# STMP3770 register map
Vendor: Freescale Semiconductor (NXP); Series: STMP37xx; File version: 1.0
CPU: other r0p0, little endian, no MPU, no FPU, 2 interrupt priority bits
Registers are 32-bit, read-write, reset 0x0 unless marked. A register's access mark holds for its fields unless they carry their own. Offsets are from the block's base; [hi:lo] are bit positions.

## CLKCTRL — STMP3770 时钟控制单元 (CLKCTRL)，管理 480MHz USB PLL、CPU/HBUS/XBUS 总线分频、各外设时钟门控与分数分频器、时钟源旁路选择及系统软复位。
Base 0x80040000
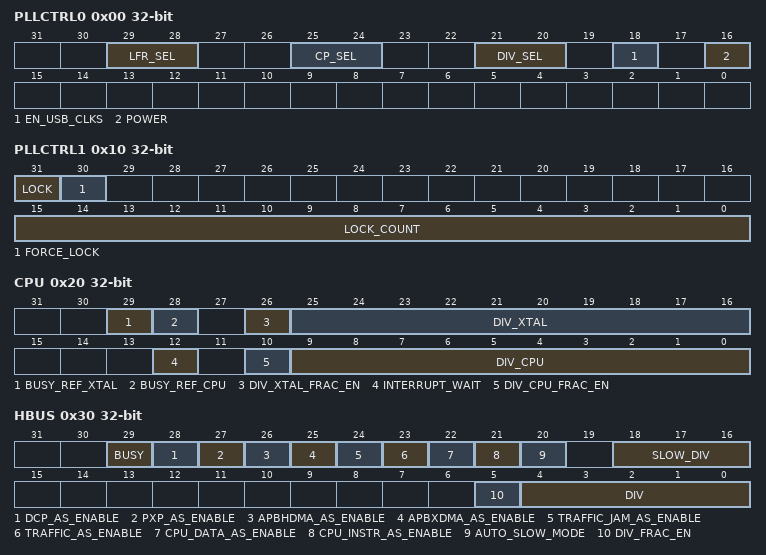
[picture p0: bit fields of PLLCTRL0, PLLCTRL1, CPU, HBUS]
0x00 PLLCTRL0 — 480MHz USB PLL 控制寄存器 0，控制 PLL 电源、USB 时钟输出使能及环路参数。
  [29:28] LFR_SEL — PLL 低频电阻选择，枚举值：DEFAULT=默认阻值，TIMES_2=2 倍阻值，TIMES_05=0.5 倍阻值，UNDEFINED=未定义。
    0=DEFAULT; 1=TIMES_2; 2=TIMES_05; 3=UNDEFINED
  [25:24] CP_SEL — PLL 电荷泵电流选择，枚举值：DEFAULT=默认电流，TIMES_2=2 倍电流，TIMES_05=0.5 倍电流，UNDEFINED=未定义。
    0=DEFAULT; 1=TIMES_2; 2=TIMES_05; 3=UNDEFINED
  [21:20] DIV_SEL — PLL 反馈分频选择，枚举值：DEFAULT=默认分频，LOWER=较低分频，LOWEST=最低分频，UNDEFINED=未定义。
    0=DEFAULT; 1=LOWER; 2=LOWEST; 3=UNDEFINED
  [18] EN_USB_CLKS — USB 时钟输出使能，置位后向 USB 模块提供 PLL 时钟。
  [16] POWER — PLL 电源使能，置位后启动 PLL 电路供电。
0x10 PLLCTRL1 — PLL 控制寄存器 1，保留寄存器，反映 PLL 锁定状态与锁定计数。
  [31] LOCK — PLL 锁定状态标志，只读，为 1 表示 PLL 已稳定锁定。
  [30] FORCE_LOCK — 强制锁定指示，置位后强制声明 PLL 锁定状态。
  [15:0] LOCK_COUNT — PLL 锁定计数器值，反映 PLL 从启动到锁定经历的计数周期。
0x20 CPU — CPU 时钟控制寄存器，配置 CPU 主时钟与晶振参考时钟的分频比。
  [29] BUSY_REF_XTAL — 晶振参考时钟分频忙标志，为 1 表示 DIV_XTAL 分频器正在更新。
  [28] BUSY_REF_CPU — CPU 参考时钟分频忙标志，为 1 表示 DIV_CPU 分频器正在更新。
  [26] DIV_XTAL_FRAC_EN — 晶振参考时钟分数分频使能，置位后启用 XTAL 路径分数分频模式。
  [25:16] DIV_XTAL — 晶振参考时钟整数分频值，用于 XTAL 旁路路径的分频。
  [12] INTERRUPT_WAIT — 中断等待模式使能，置位后 CPU 在时钟切换时等待中断完成。
  [10] DIV_CPU_FRAC_EN — CPU 时钟分数分频使能，置位后启用 CPU 分数分频模式。
  [9:0] DIV_CPU — CPU 时钟整数分频值，用于 PLL/分数时钟源路径的分频。
0x30 HBUS — AHB/APBH 总线时钟控制寄存器，配置 HBUS 分频及自动降速策略。
  [29] BUSY — HBUS 时钟分频忙标志，为 1 表示分频器正在更新。
  [28] DCP_AS_ENABLE — DCP 数据协处理器自动慢速模式使能，置位后允许 DCP 触发自动降速。
  [27] PXP_AS_ENABLE — PXP 像素处理器自动慢速模式使能，置位后允许 PXP 触发自动降速。
  [26] APBHDMA_AS_ENABLE — APBH DMA 自动慢速模式使能，置位后允许 APBH DMA 触发自动降速。
  [25] APBXDMA_AS_ENABLE — APBX DMA 自动慢速模式使能，置位后允许 APBX DMA 触发自动降速。
  [24] TRAFFIC_JAM_AS_ENABLE — 总线拥塞自动慢速模式使能，置位后允许总线拥塞触发自动降速。
  [23] TRAFFIC_AS_ENABLE — 总线流量自动慢速模式使能，置位后允许总线流量触发自动降速。
  [22] CPU_DATA_AS_ENABLE — CPU 数据访问自动慢速模式使能，置位后允许 CPU 数据访问触发自动降速。
  [21] CPU_INSTR_AS_ENABLE — CPU 指令访问自动慢速模式使能，置位后允许 CPU 取指触发自动降速。
  [20] AUTO_SLOW_MODE — 自动慢速模式使能，置位后根据总线负载自动降低 HBUS 频率。
  [18:16] SLOW_DIV — AHB 总线慢速分频选择，枚举值：BY1=1 分频，BY2=2 分频，BY4=4 分频，BY8=8 分频，BY16=16 分频，BY32=32 分频。
    0=BY1; 1=BY2; 2=BY4; 3=BY8; 4=BY16; 5=BY32
  [5] DIV_FRAC_EN — AHB 总线分数分频使能，置位后启用 HBUS 分数分频模式。
  [4:0] DIV — AHB 总线整数分频值，决定 HBUS 相对于参考源的时钟频率。
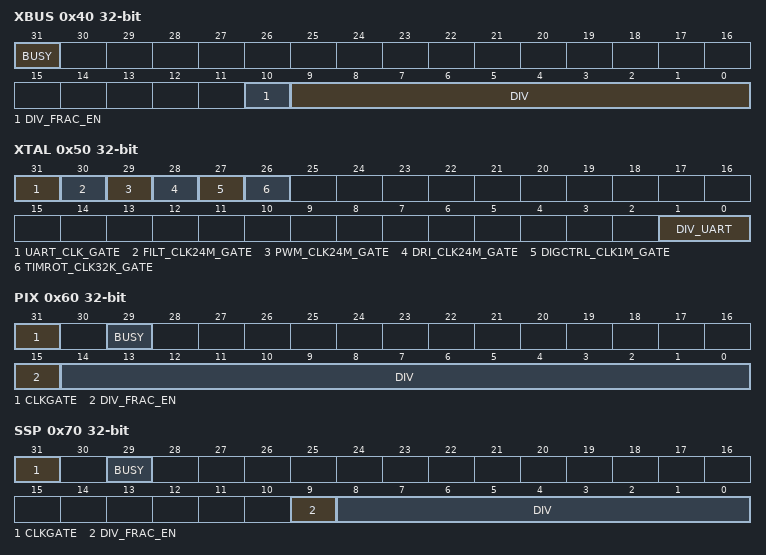
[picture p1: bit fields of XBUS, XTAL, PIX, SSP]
0x40 XBUS — APBX 总线时钟控制寄存器，配置 APBX 外设总线时钟分频。
  [31] BUSY — APBX 时钟分频忙标志，为 1 表示分频器正在更新。
  [10] DIV_FRAC_EN — APBX 总线分数分频使能，置位后启用 APBX 分数分频模式。
  [9:0] DIV — APBX 总线整数分频值，决定 APBX 相对于参考源的时钟频率。
0x50 XTAL — 24MHz 晶振时钟门控寄存器，控制各模块从 XTAL 获取的时钟门控。
  [31] UART_CLK_GATE — UART 时钟总门控，置位后关闭 UART 模块的晶振时钟。
  [30] FILT_CLK24M_GATE — FILT 24MHz 时钟门控，置位后关闭 FILT 模块的 24MHz 时钟。
  [29] PWM_CLK24M_GATE — PWM 24MHz 时钟门控，置位后关闭 PWM 模块的 24MHz 时钟。
  [28] DRI_CLK24M_GATE — DRI 24MHz 时钟门控，置位后关闭 DRI 模块的 24MHz 时钟。
  [27] DIGCTRL_CLK1M_GATE — DIGCTRL 1MHz 时钟门控，置位后关闭 DIGCTRL 模块的 1MHz 时钟。
  [26] TIMROT_CLK32K_GATE — TIMROT 32kHz 时钟门控，置位后关闭 TIMROT 模块的 32kHz 时钟。
  [1:0] DIV_UART — UART 晶振时钟分频值，决定 UART 模块从 24MHz 晶振获取的时钟分频比。
0x60 PIX — LCDIF 像素时钟控制寄存器，配置显示像素时钟分频与门控。
  [31] CLKGATE — PIX 时钟门控，置位后关闭 LCDIF 像素时钟输出。
  [29] BUSY — PIX 时钟分频忙标志，为 1 表示分频器正在更新。
  [15] DIV_FRAC_EN — PIX 像素时钟分数分频使能，置位后启用 PIX 分数分频模式。
  [14:0] DIV — PIX 像素时钟整数分频值，决定 LCDIF 像素时钟频率。
0x70 SSP — SSP 同步串行端口时钟控制寄存器，配置 SSP 外设时钟分频与门控。
  [31] CLKGATE — SSP 时钟门控，置位后关闭 SSP 外设时钟。
  [29] BUSY — SSP 时钟分频忙标志，为 1 表示分频器正在更新。
  [9] DIV_FRAC_EN — SSP 时钟分数分频使能，置位后启用 SSP 分数分频模式。
  [8:0] DIV — SSP 时钟整数分频值，决定 SSP 外设时钟频率。
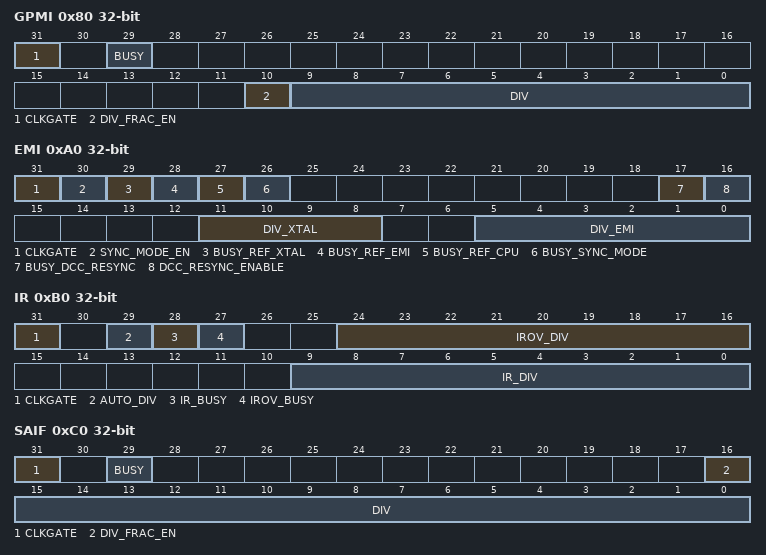
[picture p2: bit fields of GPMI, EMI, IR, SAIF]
0x80 GPMI — GPMI 通用媒体接口时钟控制寄存器，配置 GPMI 外设时钟分频与门控。
  [31] CLKGATE — GPMI 时钟门控，置位后关闭 GPMI 外设时钟。
  [29] BUSY — GPMI 时钟分频忙标志，为 1 表示分频器正在更新。
  [10] DIV_FRAC_EN — GPMI 时钟分数分频使能，置位后启用 GPMI 分数分频模式。
  [9:0] DIV — GPMI 时钟整数分频值，决定 GPMI 外设时钟频率。
0x90 SPDIF — SPDIF 数字音频接口时钟控制寄存器，仅含时钟门控控制。
  [31] CLKGATE — SPDIF 时钟门控，置位后关闭 SPDIF 模块时钟。
0xA0 EMI — EMI 外部存储器接口时钟控制寄存器，配置 EMI 时钟分频与同步模式。
  [31] CLKGATE — EMI 时钟门控，置位后关闭 EMI 模块时钟。
  [30] SYNC_MODE_EN — EMI 同步模式使能，置位后启用 EMI 同步时钟模式。
  [29] BUSY_REF_XTAL — 晶振参考时钟忙标志，为 1 表示 EMI 的 XTAL 参考分频器正在更新。
  [28] BUSY_REF_EMI — EMI 参考时钟忙标志，为 1 表示 EMI 参考分频器正在更新。
  [27] BUSY_REF_CPU — CPU 参考时钟忙标志，为 1 表示 EMI 的 CPU 参考分频器正在更新。
  [26] BUSY_SYNC_MODE — 同步模式忙标志，为 1 表示 EMI 同步模式切换正在进行。
  [17] BUSY_DCC_RESYNC — DCC 重同步忙标志，为 1 表示 DCC 重同步操作正在进行。
  [16] DCC_RESYNC_ENABLE — DCC 重同步使能，置位后启用 EMI 动态时钟校准重同步功能。
  [11:8] DIV_XTAL — EMI 晶振参考时钟整数分频值，用于 XTAL 旁路路径的分频。
  [5:0] DIV_EMI — EMI 时钟整数分频值，决定 EMI 相对于参考源的时钟频率。
0xB0 IR — 红外接口时钟控制寄存器，配置 IR 与 IROV 时钟分频及门控。
  [31] CLKGATE — IR 时钟门控，置位后关闭红外接口时钟。
  [29] AUTO_DIV — IR 自动分频使能，置位后启用 IR 时钟自动分频模式。
  [28] IR_BUSY — IR 时钟分频忙标志，为 1 表示 IR 分频器正在更新。
  [27] IROV_BUSY — IROV 时钟分频忙标志，为 1 表示 IROV 分频器正在更新。
  [24:16] IROV_DIV — IROV 红外过采样时钟整数分频值，决定红外过采样时钟频率。
  [9:0] IR_DIV — IR 红外时钟整数分频值，决定红外接口时钟频率。
0xC0 SAIF — SAIF 音频接口时钟控制寄存器，配置 SAIF 时钟分频与门控。
  [31] CLKGATE — SAIF 时钟门控，置位后关闭 SAIF 音频接口时钟。
  [29] BUSY — SAIF 时钟分频忙标志，为 1 表示分频器正在更新。
  [16] DIV_FRAC_EN — SAIF 时钟分数分频使能，置位后启用 SAIF 分数分频模式。
  [15:0] DIV — SAIF 时钟整数分频值，决定 SAIF 音频接口时钟频率。
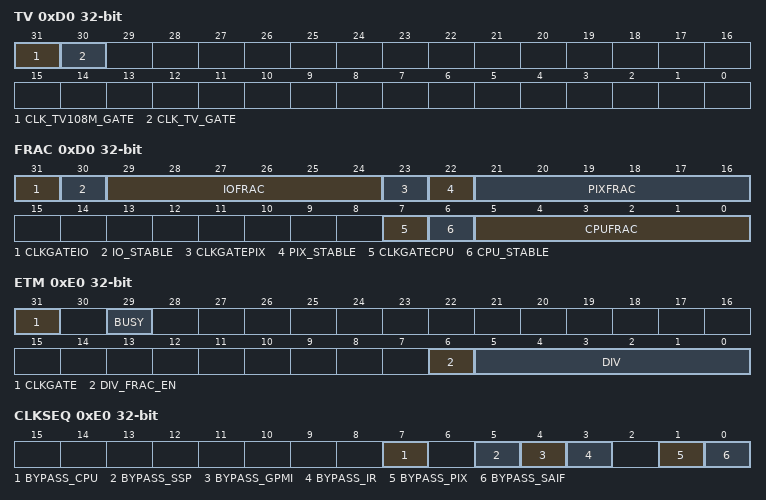
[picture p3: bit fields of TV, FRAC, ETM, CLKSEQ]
0xD0 TV (alternate view of FRAC) — TV 编码时钟控制寄存器（i.MX23 残留），控制 TV 模块时钟门控。注：该物理地址当前映射为 FRAC（分数时钟控制寄存器），TV 为遗留兼容名称。
  [31] CLK_TV108M_GATE — TV 108MHz 时钟门控，置位后关闭 TV 编码 108MHz 时钟。
  [30] CLK_TV_GATE — TV 编码时钟门控，置位后关闭 TV 编码模块时钟。
0xD0 FRAC — 分数时钟控制寄存器，配置 CPU/PIX/IO 分数分频器参数与门控。
  [31] CLKGATEIO — IO 分数时钟门控，置位后关闭 IO 分数时钟输出。
  [30] IO_STABLE — IO 分数分频稳定标志，为 1 表示 IOFRAC 分频已稳定。
  [29:24] IOFRAC — IO 分数分频值，决定 IO 分数分频器的分频比。
  [23] CLKGATEPIX — PIX 分数时钟门控，置位后关闭 PIX 分数时钟输出。
  [22] PIX_STABLE — PIX 分数分频稳定标志，为 1 表示 PIXFRAC 分频已稳定。
  [21:16] PIXFRAC — PIX 分数分频值，决定 PIX 分数分频器的分频比。
  [7] CLKGATECPU — CPU 分数时钟门控，置位后关闭 CPU 分数时钟输出。
  [6] CPU_STABLE — CPU 分数分频稳定标志，为 1 表示 CPUFRAC 分频已稳定。
  [5:0] CPUFRAC — CPU 分数分频值，决定 CPU 分数分频器的分频比。
0xE0 ETM (alternate view of CLKSEQ) — ETM 嵌入式跟踪宏单元时钟控制寄存器（i.MX23 残留），配置 ETM 时钟分频与门控。注：该物理地址当前映射为 CLKSEQ（时钟频率序列控制寄存器），ETM 为遗留兼容名称。
  [31] CLKGATE — ETM 时钟门控，置位后关闭 ETM 跟踪模块时钟。
  [29] BUSY — ETM 时钟分频忙标志，为 1 表示分频器正在更新。
  [6] DIV_FRAC_EN — ETM 时钟分数分频使能，置位后启用 ETM 分数分频模式。
  [5:0] DIV — ETM 时钟整数分频值，决定 ETM 跟踪模块时钟频率。
0xE0 CLKSEQ — 时钟频率序列控制寄存器，选择各模块时钟源是否旁路至 24MHz 晶振。
  [7] BYPASS_CPU — CPU 时钟旁路选择，0=使用 PLL/分数时钟源，1=旁路至 24MHz 晶振。
  [5] BYPASS_SSP — SSP 时钟旁路选择，0=使用 PLL/分数时钟源，1=旁路至 24MHz 晶振。
  [4] BYPASS_GPMI — GPMI 时钟旁路选择，0=使用 PLL/分数时钟源，1=旁路至 24MHz 晶振。
  [3] BYPASS_IR — IR 时钟旁路选择，0=使用 PLL/分数时钟源，1=旁路至 24MHz 晶振。
  [1] BYPASS_PIX — PIX 时钟旁路选择，0=使用 PLL/分数时钟源，1=旁路至 24MHz 晶振。
  [0] BYPASS_SAIF — SAIF 时钟旁路选择，0=使用 PLL/分数时钟源，1=旁路至 24MHz 晶振。
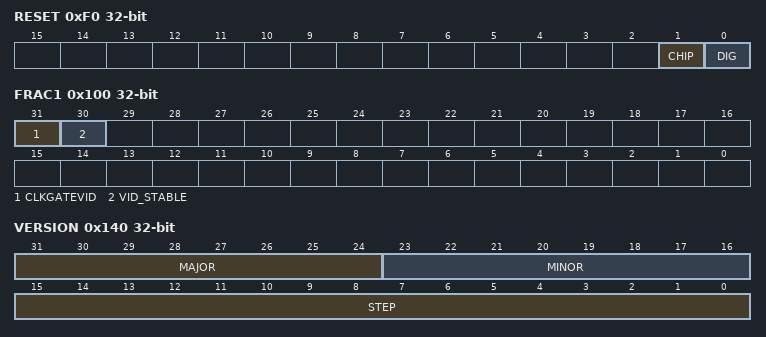
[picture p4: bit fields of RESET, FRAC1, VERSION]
0xF0 RESET — 系统软件复位寄存器，控制芯片级与数字域软复位。
  [1] CHIP — 芯片级软复位，置位后触发整芯片软复位。
  [0] DIG — 数字域软复位，置位后复位数字逻辑域。
0x100 FRAC1 — 分数时钟控制寄存器 1，控制视频分数分频器稳定与门控。
  [31] CLKGATEVID — VID 视频分数时钟门控，置位后关闭视频分数时钟输出。
  [30] VID_STABLE — VID 视频分数分频稳定标志，为 1 表示视频分数分频已稳定。
0x130 STATUS ro — 时钟控制状态寄存器，反映时钟单元运行状态。
  [31:30] CPU_LIMIT — CPU 时钟限制状态，指示当前 CPU 频率是否受到限制。
0x140 VERSION ro — 时钟控制单元版本寄存器，反映 IP 核版本信息。
  [31:24] MAJOR — IP 核主版本号。
  [23:16] MINOR — IP 核次版本号。
  [15:0] STEP — IP 核步进版本号。
